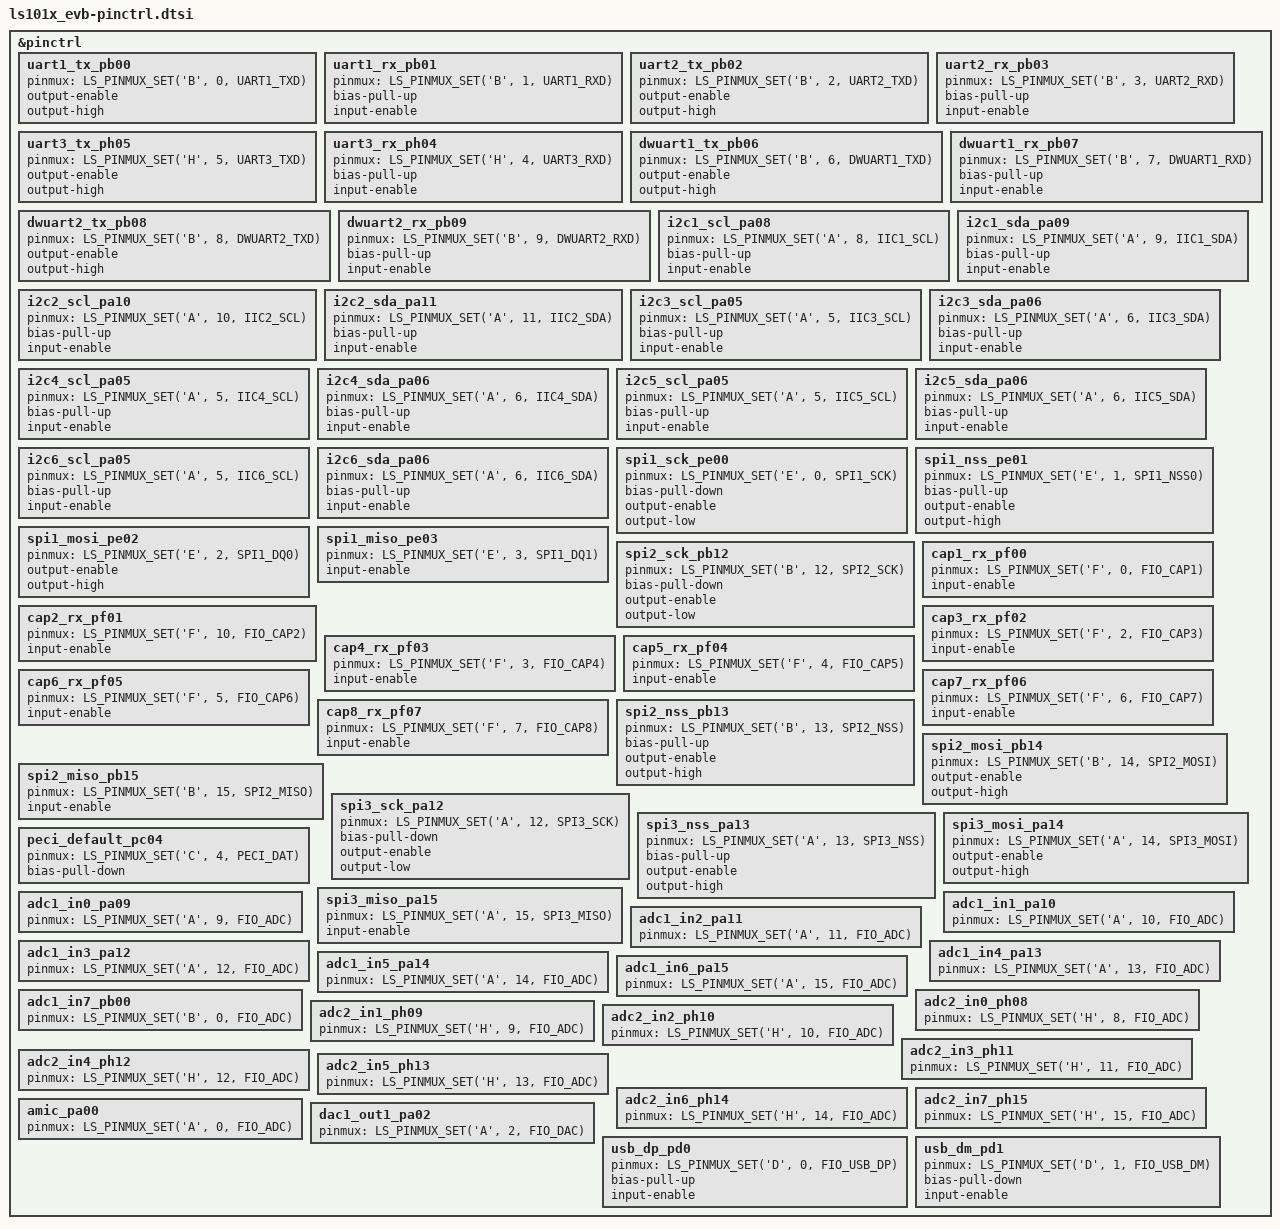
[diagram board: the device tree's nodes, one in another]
/*
 * Copyright (c) 2024  Linkedsemi
 *
 * SPDX-License-Identifier: Apache-2.0
 */

#include <linkedsemi/ls101x.dtsi>
#include <zephyr/dt-bindings/pinctrl/ls101x-pinctrl.h>

&pinctrl {
    /* UART1 */
    /omit-if-no-ref/uart1_tx_pb00: uart1_tx_pb00 {
		pinmux = <LS_PINMUX_SET('B', 0, UART1_TXD)>;
        output-enable;
        output-high;
	};
    /omit-if-no-ref/uart1_rx_pb01: uart1_rx_pb01 {
		pinmux = <LS_PINMUX_SET('B', 1, UART1_RXD)>;
        bias-pull-up;
		input-enable;
	};

    /* UART2 */
    /omit-if-no-ref/uart2_tx_pb02: uart2_tx_pb02 {
		pinmux = <LS_PINMUX_SET('B', 2, UART2_TXD)>;
        output-enable;
        output-high;
	};
	/omit-if-no-ref/uart2_rx_pb03: uart2_rx_pb03 {
		pinmux = <LS_PINMUX_SET('B', 3, UART2_RXD)>;
        bias-pull-up;
		input-enable;
	};

	/* UART3 */
	/omit-if-no-ref/uart3_tx_ph05: uart3_tx_ph05 {
		pinmux = <LS_PINMUX_SET('H', 5, UART3_TXD)>;
        output-enable;
        output-high;
	};
	/omit-if-no-ref/uart3_rx_ph04: uart3_rx_ph04 {
		pinmux = <LS_PINMUX_SET('H', 4, UART3_RXD)>;
        bias-pull-up;
        input-enable;
	};

	/* DWUART1 */
	/omit-if-no-ref/dwuart1_tx_pb06: dwuart1_tx_pb06 {
		pinmux = <LS_PINMUX_SET('B', 6, DWUART1_TXD)>;
		output-enable;
		output-high;
	};
	/omit-if-no-ref/dwuart1_rx_pb07: dwuart1_rx_pb07 {
		pinmux = <LS_PINMUX_SET('B', 7, DWUART1_RXD)>;
		bias-pull-up;
		input-enable;
	};

	/* DWUART2 */
	/omit-if-no-ref/dwuart2_tx_pb08: dwuart2_tx_pb08 {
		pinmux = <LS_PINMUX_SET('B', 8, DWUART2_TXD)>;
        output-enable;
        output-high;
	};
	/omit-if-no-ref/dwuart2_rx_pb09: dwuart2_rx_pb09 {
		pinmux = <LS_PINMUX_SET('B', 9, DWUART2_RXD)>;
        bias-pull-up;
        input-enable;
	};

    /* I2C1 */
	/omit-if-no-ref/i2c1_scl_pa08: i2c1_scl_pa08 {
		pinmux = <LS_PINMUX_SET('A', 8, IIC1_SCL)>;
		bias-pull-up;
		input-enable;
	};
	/omit-if-no-ref/i2c1_sda_pa09: i2c1_sda_pa09 {
		pinmux = <LS_PINMUX_SET('A', 9, IIC1_SDA)>;
        bias-pull-up;
		input-enable;
	};

	/* I2C2 */
	/omit-if-no-ref/i2c2_scl_pa10: i2c2_scl_pa10 {
		pinmux = <LS_PINMUX_SET('A', 10, IIC2_SCL)>;
		bias-pull-up;
		input-enable;
	};
	/omit-if-no-ref/i2c2_sda_pa11: i2c2_sda_pa11 {
		pinmux = <LS_PINMUX_SET('A', 11, IIC2_SDA)>;
        bias-pull-up;
		input-enable;
	};

    /* I2C3 */
	/omit-if-no-ref/i2c3_scl_pa05: i2c3_scl_pa05 {
		pinmux = <LS_PINMUX_SET('A', 5, IIC3_SCL)>;
		bias-pull-up;
		input-enable;
	};
	/omit-if-no-ref/i2c3_sda_pa06: i2c3_sda_pa06 {
		pinmux = <LS_PINMUX_SET('A', 6, IIC3_SDA)>;
        bias-pull-up;
		input-enable;
	};

    /* I2C4 */
	/omit-if-no-ref/i2c4_scl_pa05: i2c4_scl_pa05 {
		pinmux = <LS_PINMUX_SET('A', 5, IIC4_SCL)>;
		bias-pull-up;
		input-enable;
	};
	/omit-if-no-ref/i2c4_sda_pa06: i2c4_sda_pa06 {
		pinmux = <LS_PINMUX_SET('A', 6, IIC4_SDA)>;
        bias-pull-up;
		input-enable;
	};

    /* I2C5 */
	/omit-if-no-ref/i2c5_scl_pa05: i2c5_scl_pa05 {
		pinmux = <LS_PINMUX_SET('A', 5, IIC5_SCL)>;
		bias-pull-up;
		input-enable;
	};
	/omit-if-no-ref/i2c5_sda_pa06: i2c5_sda_pa06 {
		pinmux = <LS_PINMUX_SET('A', 6, IIC5_SDA)>;
        bias-pull-up;
		input-enable;
	};

    /* I2C6 */
	/omit-if-no-ref/i2c6_scl_pa05: i2c6_scl_pa05 {
		pinmux = <LS_PINMUX_SET('A', 5, IIC6_SCL)>;
		bias-pull-up;
		input-enable;
	};
	/omit-if-no-ref/i2c6_sda_pa06: i2c6_sda_pa06 {
		pinmux = <LS_PINMUX_SET('A', 6, IIC6_SDA)>;
        bias-pull-up;
		input-enable;
	};

	/* SPI1 */
	/omit-if-no-ref/spi1_sck_pe00: spi1_sck_pe00 {
		pinmux = <LS_PINMUX_SET('E', 0, SPI1_SCK)>;
		bias-pull-down;
		output-enable;
		output-low;
	};

	/omit-if-no-ref/ spi1_nss_pe01: spi1_nss_pe01 {
		pinmux = <LS_PINMUX_SET('E', 1, SPI1_NSS0)>;
		bias-pull-up;
        output-enable;
        output-high;
	};

    /omit-if-no-ref/spi1_mosi_pe02: spi1_mosi_pe02 {
        pinmux = <LS_PINMUX_SET('E', 2, SPI1_DQ0)>;
        output-enable;
        output-high;
    };

    /omit-if-no-ref/ spi1_miso_pe03: spi1_miso_pe03 {
        pinmux = <LS_PINMUX_SET('E', 3, SPI1_DQ1)>;
        input-enable;
    };

    /* SPI2 */
    /omit-if-no-ref/spi2_sck_pb12: spi2_sck_pb12 {
		pinmux = <LS_PINMUX_SET('B', 12, SPI2_SCK)>;
        bias-pull-down;
		output-enable;
        output-low;
	};
  
     /* CAP */
    /omit-if-no-ref/cap1_rx_pf00: cap1_rx_pf00 {
        pinmux = <LS_PINMUX_SET('F', 0, FIO_CAP1)>;
        input-enable;
    };
    /omit-if-no-ref/cap2_rx_pf01: cap2_rx_pf01 {
        pinmux = <LS_PINMUX_SET('F', 10, FIO_CAP2)>;
        input-enable;
    };
    /omit-if-no-ref/cap3_rx_pf02: cap3_rx_pf02 {
        pinmux = <LS_PINMUX_SET('F', 2, FIO_CAP3)>;
        input-enable;
    };
     /omit-if-no-ref/cap4_rx_pf03: cap4_rx_pf03 {
        pinmux = <LS_PINMUX_SET('F', 3, FIO_CAP4)>;
        input-enable;
    };
     /omit-if-no-ref/cap5_rx_pf04: cap5_rx_pf04 {
        pinmux = <LS_PINMUX_SET('F', 4, FIO_CAP5)>;
        input-enable;
    };
     /omit-if-no-ref/cap6_rx_pf05: cap6_rx_pf05 {
        pinmux = <LS_PINMUX_SET('F', 5, FIO_CAP6)>;
        input-enable;
    };
     /omit-if-no-ref/cap7_rx_pf06: cap7_rx_pf06 {
        pinmux = <LS_PINMUX_SET('F', 6, FIO_CAP7)>;
        input-enable;
    };
	 /omit-if-no-ref/ cap8_rx_pf07: cap8_rx_pf07 {
        pinmux = <LS_PINMUX_SET('F', 7, FIO_CAP8)>;
       	input-enable;
    };

    /omit-if-no-ref/ spi2_nss_pb13: spi2_nss_pb13 {
		pinmux = <LS_PINMUX_SET('B', 13, SPI2_NSS)>;
		bias-pull-up;
        output-enable;
        output-high;
	};

    /omit-if-no-ref/spi2_mosi_pb14: spi2_mosi_pb14 {
        pinmux = <LS_PINMUX_SET('B', 14, SPI2_MOSI)>;
        output-enable;
        output-high;
    };

    /omit-if-no-ref/ spi2_miso_pb15: spi2_miso_pb15 {
        pinmux = <LS_PINMUX_SET('B', 15, SPI2_MISO)>;
        input-enable;
    };

	/* SPI3 */
    /omit-if-no-ref/spi3_sck_pa12: spi3_sck_pa12 {
		pinmux = <LS_PINMUX_SET('A', 12, SPI3_SCK)>;
        bias-pull-down;
		output-enable;
        output-low;
	};

    /omit-if-no-ref/ spi3_nss_pa13: spi3_nss_pa13 {
		pinmux = <LS_PINMUX_SET('A', 13, SPI3_NSS)>;
		bias-pull-up;
        output-enable;
        output-high;
	};

    /omit-if-no-ref/spi3_mosi_pa14: spi3_mosi_pa14 {
        pinmux = <LS_PINMUX_SET('A', 14, SPI3_MOSI)>;
        output-enable;
        output-high;
    };

	/omit-if-no-ref/peci_default_pc04: peci_default_pc04 {
		pinmux = <LS_PINMUX_SET('C', 4, PECI_DAT)>;
		bias-pull-down;
	};

    /omit-if-no-ref/ spi3_miso_pa15: spi3_miso_pa15 {
        pinmux = <LS_PINMUX_SET('A', 15, SPI3_MISO)>;
        input-enable;
    };

	/omit-if-no-ref/ adc1_in0_pa09: adc1_in0_pa09 {
        pinmux = <LS_PINMUX_SET('A', 9, FIO_ADC)>;
    };

	/omit-if-no-ref/ adc1_in1_pa10: adc1_in1_pa10 {
        pinmux = <LS_PINMUX_SET('A', 10, FIO_ADC)>;
    };

	/omit-if-no-ref/ adc1_in2_pa11: adc1_in2_pa11 {
        pinmux = <LS_PINMUX_SET('A', 11, FIO_ADC)>;
    };

	/omit-if-no-ref/ adc1_in3_pa12: adc1_in3_pa12 {
        pinmux = <LS_PINMUX_SET('A', 12, FIO_ADC)>;
    };

	/omit-if-no-ref/ adc1_in4_pa13: adc1_in4_pa13 {
        pinmux = <LS_PINMUX_SET('A', 13, FIO_ADC)>;
    };
	
	/omit-if-no-ref/ adc1_in5_pa14: adc1_in5_pa14 {
        pinmux = <LS_PINMUX_SET('A', 14, FIO_ADC)>;
    };

	/omit-if-no-ref/ adc1_in6_pa15: adc1_in6_pa15 {
        pinmux = <LS_PINMUX_SET('A', 15, FIO_ADC)>;
    };

	/omit-if-no-ref/ adc1_in7_pb00: adc1_in7_pb00 {
        pinmux = <LS_PINMUX_SET('B', 0, FIO_ADC)>;
    };

	/omit-if-no-ref/ adc2_in0_ph08: adc2_in0_ph08 {
        pinmux = <LS_PINMUX_SET('H', 8, FIO_ADC)>;
    };

	/omit-if-no-ref/ adc2_in1_ph09: adc2_in1_ph09 {
        pinmux = <LS_PINMUX_SET('H', 9, FIO_ADC)>;
    };

	/omit-if-no-ref/ adc2_in2_ph10: adc2_in2_ph10 {
        pinmux = <LS_PINMUX_SET('H', 10, FIO_ADC)>;
    };

	/omit-if-no-ref/ adc2_in3_ph11: adc2_in3_ph11 {
        pinmux = <LS_PINMUX_SET('H', 11, FIO_ADC)>;
    };

	/omit-if-no-ref/ adc2_in4_ph12: adc2_in4_ph12 {
        pinmux = <LS_PINMUX_SET('H', 12, FIO_ADC)>;
    };

	/omit-if-no-ref/ adc2_in5_ph13: adc2_in5_ph13 {
        pinmux = <LS_PINMUX_SET('H', 13, FIO_ADC)>;
    };

	/omit-if-no-ref/ adc2_in6_ph14: adc2_in6_ph14 {
        pinmux = <LS_PINMUX_SET('H', 14, FIO_ADC)>;
    };

	/omit-if-no-ref/ adc2_in7_ph15: adc2_in7_ph15 {
        pinmux = <LS_PINMUX_SET('H', 15, FIO_ADC)>;
    };

	/omit-if-no-ref/ amic_pa00: amic_pa00 {
        pinmux = <LS_PINMUX_SET('A', 0, FIO_ADC)>;
    };

	/omit-if-no-ref/ dac1_out1_pa02: dac1_out1_pa02 {
        pinmux = <LS_PINMUX_SET('A', 2, FIO_DAC)>;
    };

    /omit-if-no-ref/ usb_dp_pd0: usb_dp_pd0 {
        pinmux = <LS_PINMUX_SET('D', 0, FIO_USB_DP)>;
		bias-pull-up;
		input-enable;
    };

    /omit-if-no-ref/ usb_dm_pd1: usb_dm_pd1 {
        pinmux = <LS_PINMUX_SET('D', 1, FIO_USB_DM)>;
		bias-pull-down;
		input-enable;
    };
};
